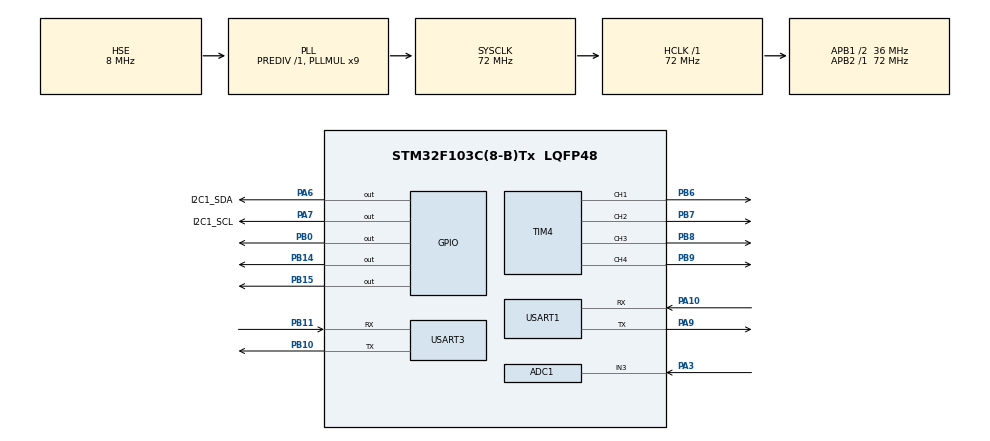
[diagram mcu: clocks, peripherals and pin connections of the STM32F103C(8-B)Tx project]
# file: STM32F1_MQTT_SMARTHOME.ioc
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ADC1.Channel-0\#ChannelRegularConversion=ADC_CHANNEL_3
ADC1.NbrOfConversion=1
ADC1.NbrOfConversionFlag=1
ADC1.Rank-0\#ChannelRegularConversion=1
ADC1.SamplingTime-0\#ChannelRegularConversion=ADC_SAMPLETIME_239CYCLES_5
ADC1.master=1
Mcu.Family=STM32F1
Mcu.Name=STM32F103C(8-B)Tx
Mcu.Package=LQFP48
NVIC.PriorityGroup=NVIC_PRIORITYGROUP_4
NVIC.USART1_IRQn=true\:0\:0\:false\:false\:true\:true\:true
NVIC.USART3_IRQn=true\:0\:0\:false\:false\:true\:true\:true
PA10.Mode=Asynchronous
PA10.Signal=USART1_RX
PA13.Mode=Serial_Wire
PA13.Signal=SYS_JTMS-SWDIO
PA14.Mode=Serial_Wire
PA14.Signal=SYS_JTCK-SWCLK
PA3.Signal=ADCx_IN3
PA6.GPIO_Label=I2C1_SDA
PA6.GPIO_ModeDefaultOutputPP=GPIO_MODE_OUTPUT_OD
PA6.GPIO_Speed=GPIO_SPEED_FREQ_HIGH
PA6.PinState=GPIO_PIN_SET
PA6.Signal=GPIO_Output
PA7.GPIO_Label=I2C1_SCL
PA7.GPIO_ModeDefaultOutputPP=GPIO_MODE_OUTPUT_OD
PA7.GPIO_Speed=GPIO_SPEED_FREQ_HIGH
PA7.PinState=GPIO_PIN_SET
PA7.Signal=GPIO_Output
PA9.Mode=Asynchronous
PA9.Signal=USART1_TX
PB0.Signal=GPIO_Output
PB10.Mode=Asynchronous
PB10.Signal=USART3_TX
PB11.Mode=Asynchronous
PB11.Signal=USART3_RX
PB14.Signal=GPIO_Output
PB15.Signal=GPIO_Output
PB6.GPIO_ModeDefaultPP=GPIO_MODE_AF_PP
PB6.GPIO_Speed=GPIO_SPEED_FREQ_HIGH
PB6.Signal=S_TIM4_CH1
PB7.GPIO_ModeDefaultPP=GPIO_MODE_AF_PP
PB7.GPIO_Speed=GPIO_SPEED_FREQ_HIGH
PB7.Signal=S_TIM4_CH2
PB8.GPIO_ModeDefaultPP=GPIO_MODE_AF_PP
PB8.GPIO_Speed=GPIO_SPEED_FREQ_HIGH
PB8.Signal=S_TIM4_CH3
PB9.GPIO_ModeDefaultPP=GPIO_MODE_AF_PP
PB9.GPIO_Speed=GPIO_SPEED_FREQ_HIGH
PB9.Signal=S_TIM4_CH4
PD0-OSC_IN.Mode=HSE-External-Oscillator
PD0-OSC_IN.Signal=RCC_OSC_IN
PD1-OSC_OUT.Mode=HSE-External-Oscillator
PD1-OSC_OUT.Signal=RCC_OSC_OUT
ProjectManager.HeapSize=0x200
ProjectManager.StackSize=0x400
ProjectManager.TargetToolchain=STM32CubeIDE
RCC.ADCPresc=RCC_ADCPCLK2_DIV6
RCC.AHBFreq_Value=72000000
RCC.APB1CLKDivider=RCC_HCLK_DIV2
RCC.APB1Freq_Value=36000000
RCC.APB1TimFreq_Value=72000000
RCC.APB2Freq_Value=72000000
RCC.APB2TimFreq_Value=72000000
RCC.HCLKFreq_Value=72000000
RCC.PLLMUL=RCC_PLL_MUL9
RCC.PLLSourceVirtual=RCC_PLLSOURCE_HSE
RCC.SYSCLKFreq_VALUE=72000000
RCC.SYSCLKSource=RCC_SYSCLKSOURCE_PLLCLK
RCC.USBFreq_Value=72000000
SH.ADCx_IN3.0=ADC1_IN3,IN3
SH.S_TIM4_CH1.0=TIM4_CH1,PWM Generation1 CH1
SH.S_TIM4_CH2.0=TIM4_CH2,PWM Generation2 CH2
SH.S_TIM4_CH3.0=TIM4_CH3,PWM Generation3 CH3
SH.S_TIM4_CH4.0=TIM4_CH4,PWM Generation4 CH4
TIM4.Channel-PWM\ Generation1\ CH1=TIM_CHANNEL_1
TIM4.Channel-PWM\ Generation2\ CH2=TIM_CHANNEL_2
TIM4.Channel-PWM\ Generation3\ CH3=TIM_CHANNEL_3
TIM4.Channel-PWM\ Generation4\ CH4=TIM_CHANNEL_4
USART1.VirtualMode=VM_ASYNC
USART3.VirtualMode=VM_ASYNC
VP_TIM4_VS_ClockSourceINT.Mode=Internal
board=custom

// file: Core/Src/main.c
/* USER CODE BEGIN Header */
/**
 ******************************************************************************
 * @file           : main.c
 * @brief          : Main program body
 ******************************************************************************
 * @attention
 *
 * <h2><center>&copy; Copyright (c) 2020 STMicroelectronics.
 * All rights reserved.</center></h2>
 *
 * This software component is licensed by ST under BSD 3-Clause license,
 * the "License"; You may not use this file except in compliance with the
 * License. You may obtain a copy of the License at:
 *                        opensource.org/licenses/BSD-3-Clause
 *
 ******************************************************************************
 */
/* USER CODE END Header */

#include "main.h"
#include "adc.h"
#include "tim.h"
#include "usart.h"
#include "gpio.h"

/* USER CODE BEGIN Includes */
#include "oled.h"
#include "my_func.h"
#include "SHT2X.h"
#include "tim.h"
/* USER CODE END Includes */

/* USER CODE BEGIN PV */
//extern s8 temperatureC;
//extern u8 humidityRH;
/* USER CODE END PV */

void SystemClock_Config(void);

int main(void) {
	/* USER CODE BEGIN 1 */
	u8 show_str[50];
	/* USER CODE END 1 */

	/* MCU Configuration--------------------------------------------------------*/

	/* Reset of all peripherals, Initializes the Flash interface and the Systick. */
	HAL_Init();

	/* Configure the system clock */
	SystemClock_Config();

	/* Initialize all configured peripherals */
	MX_GPIO_Init();
	MX_ADC1_Init();
	MX_TIM4_Init();
	MX_USART1_UART_Init();
	MX_USART3_UART_Init();

	/* USER CODE BEGIN 2 */
	OLED_Init();

//	__HAL_TIM_SetCompare(&htim4,TIM_CHANNEL_1,200);
	OLED_ShowString(0, 0, (u8*) "hello world");
	OLED_Clear();
//	while(!ESP_8266_CHECK())
//	{
//		OLED_ShowString(0, 0, (u8*) "Waitting for Network");
//	}
//      printf("\r\n hello world!\r\n");
	/* USER CODE END 2 */

	/* Infinite loop */
	/* USER CODE BEGIN WHILE */
	while (1) {
		Get_Sensor_Data();
		Oled_show();
		LEDR_ON(50);
		LEDG_ON(200);
		LEDB_ON(250);
//		Data_publish();
//		if(	Get_Ctrl_Data())
//			Ctrl_task();
//		sprintf(show_str,"%d,%d",temperatureC,humidityRH);
//		OLED_ShowString(0, 2, show_str);
		/* USER CODE END WHILE */

	}
}

void SystemClock_Config(void) {
	RCC_OscInitTypeDef RCC_OscInitStruct = { 0 };
	RCC_ClkInitTypeDef RCC_ClkInitStruct = { 0 };
	RCC_PeriphCLKInitTypeDef PeriphClkInit = { 0 };

	/** Initializes the CPU, AHB and APB busses clocks
	 */
	RCC_OscInitStruct.OscillatorType = RCC_OSCILLATORTYPE_HSE;
	RCC_OscInitStruct.HSEState = RCC_HSE_ON;
	RCC_OscInitStruct.HSEPredivValue = RCC_HSE_PREDIV_DIV1;
	RCC_OscInitStruct.HSIState = RCC_HSI_ON;
	RCC_OscInitStruct.PLL.PLLState = RCC_PLL_ON;
	RCC_OscInitStruct.PLL.PLLSource = RCC_PLLSOURCE_HSE;
	RCC_OscInitStruct.PLL.PLLMUL = RCC_PLL_MUL9;
	if (HAL_RCC_OscConfig(&RCC_OscInitStruct) != HAL_OK) {
		Error_Handler();
	}
	/** Initializes the CPU, AHB and APB busses clocks
	 */
	RCC_ClkInitStruct.ClockType = RCC_CLOCKTYPE_HCLK | RCC_CLOCKTYPE_SYSCLK
			| RCC_CLOCKTYPE_PCLK1 | RCC_CLOCKTYPE_PCLK2;
	RCC_ClkInitStruct.SYSCLKSource = RCC_SYSCLKSOURCE_PLLCLK;
	RCC_ClkInitStruct.AHBCLKDivider = RCC_SYSCLK_DIV1;
	RCC_ClkInitStruct.APB1CLKDivider = RCC_HCLK_DIV2;
	RCC_ClkInitStruct.APB2CLKDivider = RCC_HCLK_DIV1;

	if (HAL_RCC_ClockConfig(&RCC_ClkInitStruct, FLASH_LATENCY_2) != HAL_OK) {
		Error_Handler();
	}
	PeriphClkInit.PeriphClockSelection = RCC_PERIPHCLK_ADC;
	PeriphClkInit.AdcClockSelection = RCC_ADCPCLK2_DIV6;
	if (HAL_RCCEx_PeriphCLKConfig(&PeriphClkInit) != HAL_OK) {
		Error_Handler();
	}
}

void Error_Handler(void) {
}

/************************ (C) COPYRIGHT STMicroelectronics *****END OF FILE****/
